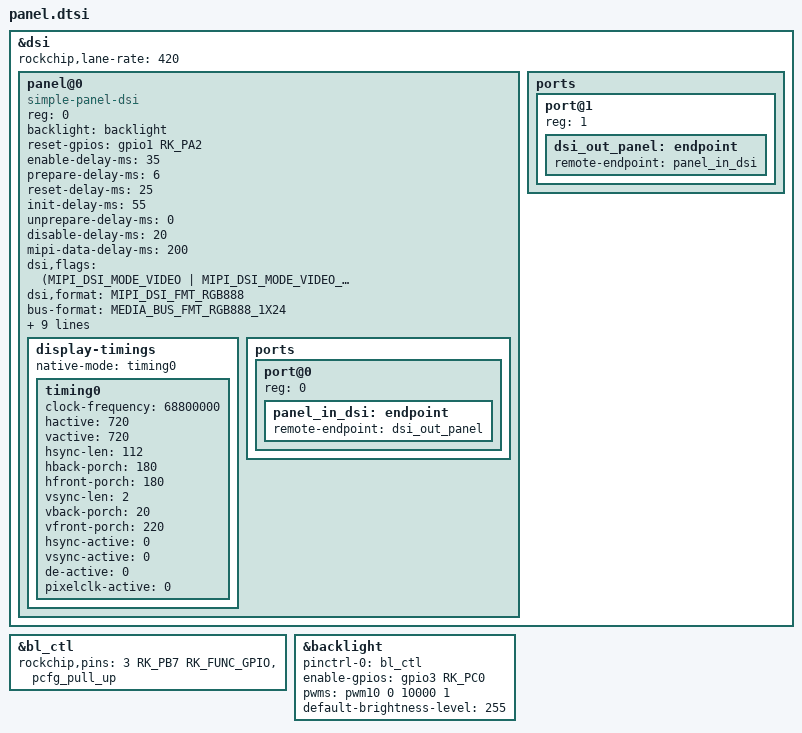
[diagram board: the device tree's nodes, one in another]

&dsi {
	status = "okay";
	rockchip,lane-rate  = <420>;

	// TIANMA TM041XDHC02
	panel@0 {
		status = "okay";
		compatible = "simple-panel-dsi";

		reg = <0>;
		backlight = <&backlight>;
		/delete-property/ power-supply;
		/delete-property/ enable-gpios;
		reset-gpios = <&gpio1 RK_PA2 GPIO_ACTIVE_HIGH>;

		enable-delay-ms = <35>;
		prepare-delay-ms = <6>;
		reset-delay-ms = <25>;
		init-delay-ms = <55>;
		unprepare-delay-ms = <0>;
		disable-delay-ms = <20>;
		mipi-data-delay-ms = <200>;
		dsi,flags = <(MIPI_DSI_MODE_VIDEO | MIPI_DSI_MODE_VIDEO_BURST | MIPI_DSI_MODE_LPM | MIPI_DSI_MODE_EOT_PACKET)>;
		dsi,format = <MIPI_DSI_FMT_RGB888>;
		bus-format = <MEDIA_BUS_FMT_RGB888_1X24>;
		dsi,lanes  = <4>;

		width-mm = <74>;
		height-mm = <74>;
		size,width = <74>;
		size,height = <74>;

		// 05 dsc short wr, 0 param
		// 15 dcs short wr, 1 param
		// 39 dcs long wr, >= 2

		panel-init-sequence = [
			39 00 04  FF 98 81 01 
			15 00 02  00 4a         
			15 00 02  01 33 
			15 00 02  02 00 
			15 00 02  03 00 
			15 00 02  04 ce 
			15 00 02  05 13 
			15 00 02  06 00 
			15 00 02  07 00 
			15 00 02  08 86         
			15 00 02  09 01         
			15 00 02  0a 73 
			15 00 02  0b 00 
			15 00 02  0c 08      
			15 00 02  0d 08               
			15 00 02  0e 00    
			15 00 02  0f 00 
			15 00 02  24 ce 
			15 00 02  25 0b 
			15 00 02  26 00 
			15 00 02  27 00 
			15 00 02  31 0C 
			15 00 02  32 24  
			15 00 02  33 02 
			15 00 02  34 02  
			15 00 02  35 02 
			15 00 02  36 00 
			15 00 02  37 01 
			15 00 02  38 13 
			15 00 02  39 11 
			15 00 02  3a 17 
			15 00 02  3b 15 
			15 00 02  3c 09 
			15 00 02  3d 0B 
			15 00 02  3e 07 
			15 00 02  3f 07 
			15 00 02  40 07     
			15 00 02  41 07      
			15 00 02  42 07 
			15 00 02  43 07  
			15 00 02  44 07       
			15 00 02  45 07       
			15 00 02  46 07 
			15 00 02  47 0C 
			15 00 02  48 24 
			15 00 02  49 02 
			15 00 02  4a 02 
			15 00 02  4b 02 
			15 00 02  4c 00 
			15 00 02  4d 01 
			15 00 02  4e 12 
			15 00 02  4f 10 
			15 00 02  50 16 
			15 00 02  51 14 
			15 00 02  52 08 
			15 00 02  53 0A 
			15 00 02  54 07 
			15 00 02  55 07 
			15 00 02  56 07 
			15 00 02  57 07 
			15 00 02  58 07       
			15 00 02  59 07      
			15 00 02  5a 07 
			15 00 02  5b 07 
			15 00 02  5c 07      
			15 00 02  61 0C      
			15 00 02  62 24 
			15 00 02  63 02 
			15 00 02  64 02      
			15 00 02  65 02       
			15 00 02  66 00 
			15 00 02  67 01 
			15 00 02  68 14     
			15 00 02  69 16   
			15 00 02  6a 10 
			15 00 02  6b 12 
			15 00 02  6c 0A     
			15 00 02  6d 08   
			15 00 02  6e 07 
			15 00 02  6f 07 
			15 00 02  70 07     
			15 00 02  71 07       
			15 00 02  72 07 
			15 00 02  73 07 
			15 00 02  74 07       
			15 00 02  75 07       
			15 00 02  76 07 
			15 00 02  77 0C 
			15 00 02  78 24     
			15 00 02  79 02   
			15 00 02  7a 02 
			15 00 02  7b 02 
			15 00 02  7c 00 
			15 00 02  7d 01 
			15 00 02  7e 15 
			15 00 02  7f 17 
			15 00 02  80 11 
			15 00 02  81 13 
			15 00 02  82 0B 
			15 00 02  83 09     
			15 00 02  84 07 
			15 00 02  85 07 
			15 00 02  86 07 
			15 00 02  87 07 
			15 00 02  88 07     
			15 00 02  89 07       
			15 00 02  8a 07 
			15 00 02  8b 07 
			15 00 02  8c 07 
			39 00 04  FF 98 81 0E 
			15 00 02  02 0C 
			15 00 02  01 90 
			15 00 02  13 05 
			39 00 04  FF 98 81 05 
			15 00 02  03 00 
			15 00 02  04 cd 
			15 00 02  58 61 
			15 00 02  63 88 
			15 00 02  64 88 
			15 00 02  68 65 
			15 00 02  69 6B 
			15 00 02  6A 79 
			15 00 02  6B 57 
			15 00 02  5D 07 
			39 00 04  FF 98 81 06 
			15 00 02  2E 01 
			15 00 02  C0 67 
			15 00 02  C1 01 
			15 00 02  D6 85 
			15 00 02  27 14 
			15 00 02  28 14 
			15 00 02  11 03 
			15 00 02  13 45  
			15 00 02  14 41 
			15 00 02  15 F1  
			15 00 02  16 40 
			15 00 02  17 48 
			15 00 02  18 3B 
			39 00 04  FF 98 81 01 
			15 00 02  E7 54 
			39 00 04  FF 98 81 02 
			15 00 02  4B 5A  
			15 00 02  4D 4E 
			15 00 02  1A 48 
			39 00 04  FF 98 81 06 
			15 00 02  27 20 
			15 00 02  28 20 
			15 00 02  48 0F 
			15 00 02  4D 80 
			15 00 02  4E 40 
			15 00 02  7C 40 
			39 00 04  FF 98 81 07 
			15 00 02  0F 02  
			39 00 04  FF 98 81 0E 
			15 00 02  01 28 
			15 00 02  C1 80 
			39 00 04  FF 98 81 08 
			39 00 1C  E0 00 24 65 84 b8 54 e4 08 34 58 95 93 Bf Ec 13 AA 3d 72 97 C3 FE EC 22 68 a2 03 EC 
			39 00 1C  E1 00 24 65 84 b8 54 e4 08 34 58 95 93 Bf Ec 13 AA 3d 72 97 C3 FE EC 22 68 a2 03 EC 
			39 00 04  FF 98 81 00 
			05 78 01  11
			05 32 01  29
			15 00 02  35 00  
		];

		panel-exit-sequence = [
			05 00 01 28
			05 00 01 10
		];

		display-timings {
			native-mode = <&timing0>;
			timing0: timing0 {
				clock-frequency = <68800000>;
				hactive = <720>;
				vactive = <720>;

				hsync-len = <112>;
				hback-porch = <180>;
				hfront-porch = <180>;

				vsync-len = <2>;
				vback-porch = <20>;
				vfront-porch = <220>;

				hsync-active = <0>;
				vsync-active = <0>;
				de-active = <0>;
				pixelclk-active = <0>;
			};
		};

		ports {
			#address-cells = <1>;
			#size-cells = <0>;

			port@0 {
				reg = <0>;
				panel_in_dsi: endpoint {
					remote-endpoint = <&dsi_out_panel>;
				};
			};
		};
	};

	ports {
		#address-cells = <1>;
		#size-cells = <0>;

		port@1 {
			reg = <1>;
			dsi_out_panel: endpoint {
				remote-endpoint = <&panel_in_dsi>;
			};
		};
	};

};

&bl_ctl {
	rockchip,pins =
		<3 RK_PB7 RK_FUNC_GPIO &pcfg_pull_up>;
};

&backlight {
	pinctrl-0 = <&bl_ctl>;
	enable-gpios = <&gpio3 RK_PC0 GPIO_ACTIVE_HIGH>;
	pwms = <&pwm10 0 10000 1>;
	default-brightness-level = <255>;
};
